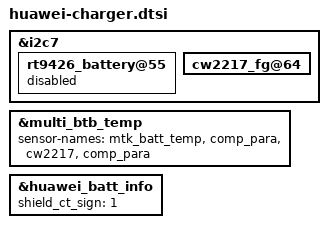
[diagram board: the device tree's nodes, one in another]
#include "../huawei_charger/mt6853_hjc_huawei_charger.dtsi"

&i2c7 {
	rt9426_battery@55{
		status = "disabled";
	};
	cw2217_fg@64 {
		status = "ok";
	};
};

&multi_btb_temp {
	sensor-names =
		"mtk_batt_temp", "comp_para",
		"cw2217", "comp_para";
};

&huawei_batt_info {
	shield_ct_sign = <1>;
};
